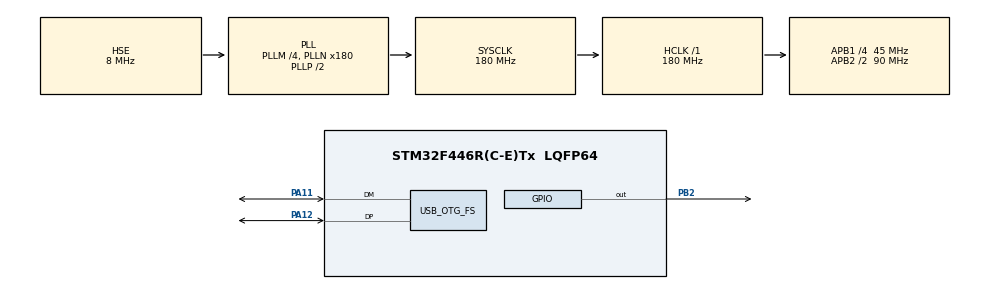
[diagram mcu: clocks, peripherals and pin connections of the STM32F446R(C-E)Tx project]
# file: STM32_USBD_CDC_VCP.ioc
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Mcu.Family=STM32F4
Mcu.Name=STM32F446R(C-E)Tx
Mcu.Package=LQFP64
NVIC.OTG_FS_IRQn=true\:0\:0\:false\:false\:true\:false\:true\:true
NVIC.PriorityGroup=NVIC_PRIORITYGROUP_4
PA11.Mode=Device_Only
PA11.Signal=USB_OTG_FS_DM
PA12.Mode=Device_Only
PA12.Signal=USB_OTG_FS_DP
PA13.Mode=Serial_Wire
PA13.Signal=SYS_JTMS-SWDIO
PA14.Mode=Serial_Wire
PA14.Signal=SYS_JTCK-SWCLK
PB2.Signal=GPIO_Output
PH0-OSC_IN.Mode=HSE-External-Oscillator
PH0-OSC_IN.Signal=RCC_OSC_IN
PH1-OSC_OUT.Mode=HSE-External-Oscillator
PH1-OSC_OUT.Signal=RCC_OSC_OUT
ProjectManager.HeapSize=0x200
ProjectManager.StackSize=0x400
ProjectManager.TargetToolchain=STM32CubeIDE
RCC.AHBFreq_Value=180000000
RCC.APB1CLKDivider=RCC_HCLK_DIV4
RCC.APB1Freq_Value=45000000
RCC.APB1TimFreq_Value=90000000
RCC.APB2CLKDivider=RCC_HCLK_DIV2
RCC.APB2Freq_Value=90000000
RCC.APB2TimFreq_Value=180000000
RCC.CortexFreq_Value=180000000
RCC.HCLKFreq_Value=180000000
RCC.HSE_VALUE=8000000
RCC.PLLM=4
RCC.PLLN=180
RCC.PLLQ=7
RCC.PLLSAIM=8
RCC.PLLSAIP=RCC_PLLSAIP_DIV4
RCC.PLLSourceVirtual=RCC_PLLSOURCE_HSE
RCC.SYSCLKFreq_VALUE=180000000
RCC.SYSCLKSource=RCC_SYSCLKSOURCE_PLLCLK
RCC.USBCLockSelection=RCC_CLK48CLKSOURCE_PLLSAIP
RCC.USBFreq_Value=48000000
RCC.VCOOutputFreq_Value=360000000
USB_DEVICE.APP_RX_DATA_SIZE-CDC_FS=512
USB_DEVICE.APP_TX_DATA_SIZE-CDC_FS=512
USB_DEVICE.CLASS_NAME_FS=CDC
USB_DEVICE.USBD_SELF_POWERED-CDC_FS=1
USB_DEVICE.VirtualMode-CDC_FS=Cdc
USB_DEVICE.VirtualModeFS=Cdc_FS
USB_OTG_FS.VirtualMode=Device_Only
VP_USB_DEVICE_VS_USB_DEVICE_CDC_FS.Mode=CDC_FS
board=custom

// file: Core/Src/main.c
/* USER CODE BEGIN Header */
/**
  ******************************************************************************
  * @file           : main.c
  * @brief          : Main program body
  ******************************************************************************
  * @attention
  *
  * Copyright (c) 2026 STMicroelectronics.
  * All rights reserved.
  *
  * This software is licensed under terms that can be found in the LICENSE file
  * in the root directory of this software component.
  * If no LICENSE file comes with this software, it is provided AS-IS.
  *
  ******************************************************************************
  */
/* USER CODE END Header */
#include "main.h"
#include "usb_device.h"

/* USER CODE BEGIN Includes */
#include "usbd_cdc_if.h"
#include "string.h"
/* USER CODE END Includes */

void SystemClock_Config(void);
static void MX_GPIO_Init(void);

/* USER CODE BEGIN 0 */
extern uint8_t UserRxBufferFS[APP_RX_DATA_SIZE];
extern uint8_t recvDone;
extern uint32_t recvLen;

int _write(int file, char *ptr, int len)
{
	if (CDC_Transmit_FS((uint8_t *)ptr, len) == USBD_BUSY)
	{
		HAL_Delay(1);
	}
	return len;
}

int testNum = 1234;

/* USER CODE END 0 */

int main(void)
{

  /* MCU Configuration--------------------------------------------------------*/

  /* Reset of all peripherals, Initializes the Flash interface and the Systick. */
  HAL_Init();

  /* Configure the system clock */
  SystemClock_Config();

  /* Initialize all configured peripherals */
  MX_GPIO_Init();
  MX_USB_DEVICE_Init();

  /* Infinite loop */
  while (1)
  {

    /* USER CODE BEGIN 3 */

	  if (recvDone == 1)
	  {
		  recvDone = 0;
		  if (strncmp((char *)UserRxBufferFS, "ON", recvLen) == 0)
		  {
			  HAL_GPIO_WritePin(GPIOB, GPIO_PIN_2, 1);
			  CDC_Transmit_FS((uint8_t *)"LED Turned ON\n", 16);
		  }

		  else if (strncmp((char *)UserRxBufferFS, "OFF", recvLen) == 0)
		  {
			  HAL_GPIO_WritePin(GPIOB, GPIO_PIN_2, 0);
			  CDC_Transmit_FS((uint8_t *)"LED Turned OFF\n", 17);
		  }
	  }

//	  CDC_Transmit_FS((uint8_t *)"Hello World\n", 12);
//	  HAL_Delay(1000);

	  printf ("Printing via printf() %d\r\n", testNum);
	  HAL_Delay(1000);

  }
  /* USER CODE END 3 */
}

void SystemClock_Config(void)
{
  RCC_OscInitTypeDef RCC_OscInitStruct = {0};
  RCC_ClkInitTypeDef RCC_ClkInitStruct = {0};

  /** Configure the main internal regulator output voltage
  */
  __HAL_RCC_PWR_CLK_ENABLE();
  __HAL_PWR_VOLTAGESCALING_CONFIG(PWR_REGULATOR_VOLTAGE_SCALE1);

  /** Initializes the RCC Oscillators according to the specified parameters
  * in the RCC_OscInitTypeDef structure.
  */
  RCC_OscInitStruct.OscillatorType = RCC_OSCILLATORTYPE_HSE;
  RCC_OscInitStruct.HSEState = RCC_HSE_ON;
  RCC_OscInitStruct.PLL.PLLState = RCC_PLL_ON;
  RCC_OscInitStruct.PLL.PLLSource = RCC_PLLSOURCE_HSE;
  RCC_OscInitStruct.PLL.PLLM = 4;
  RCC_OscInitStruct.PLL.PLLN = 180;
  RCC_OscInitStruct.PLL.PLLP = RCC_PLLP_DIV2;
  RCC_OscInitStruct.PLL.PLLQ = 7;
  RCC_OscInitStruct.PLL.PLLR = 2;
  if (HAL_RCC_OscConfig(&RCC_OscInitStruct) != HAL_OK)
  {
    Error_Handler();
  }

  /** Activate the Over-Drive mode
  */
  if (HAL_PWREx_EnableOverDrive() != HAL_OK)
  {
    Error_Handler();
  }

  /** Initializes the CPU, AHB and APB buses clocks
  */
  RCC_ClkInitStruct.ClockType = RCC_CLOCKTYPE_HCLK|RCC_CLOCKTYPE_SYSCLK
                              |RCC_CLOCKTYPE_PCLK1|RCC_CLOCKTYPE_PCLK2;
  RCC_ClkInitStruct.SYSCLKSource = RCC_SYSCLKSOURCE_PLLCLK;
  RCC_ClkInitStruct.AHBCLKDivider = RCC_SYSCLK_DIV1;
  RCC_ClkInitStruct.APB1CLKDivider = RCC_HCLK_DIV4;
  RCC_ClkInitStruct.APB2CLKDivider = RCC_HCLK_DIV2;

  if (HAL_RCC_ClockConfig(&RCC_ClkInitStruct, FLASH_LATENCY_5) != HAL_OK)
  {
    Error_Handler();
  }
}

static void MX_GPIO_Init(void)
{
  GPIO_InitTypeDef GPIO_InitStruct = {0};

  /* GPIO Ports Clock Enable */
  __HAL_RCC_GPIOH_CLK_ENABLE();
  __HAL_RCC_GPIOB_CLK_ENABLE();
  __HAL_RCC_GPIOA_CLK_ENABLE();

  /*Configure GPIO pin Output Level */
  HAL_GPIO_WritePin(GPIOB, GPIO_PIN_2, GPIO_PIN_RESET);

  /*Configure GPIO pin : PB2 */
  GPIO_InitStruct.Pin = GPIO_PIN_2;
  GPIO_InitStruct.Mode = GPIO_MODE_OUTPUT_PP;
  GPIO_InitStruct.Pull = GPIO_NOPULL;
  GPIO_InitStruct.Speed = GPIO_SPEED_FREQ_LOW;
  HAL_GPIO_Init(GPIOB, &GPIO_InitStruct);

}

void Error_Handler(void)
{
  __disable_irq();
  while (1)
  {
  }
}
